AUTOSAR XML (schema 4-1-3)
standard types defined: boolean, sint16, uint16, uint8
package /DataTypes
  impl type Array_unit16_4: category=ARRAY, sw-calibration-access=READ-ONLY, type-emitter=RTE
    element Array_unit16_4: array-size=4, array-size-semantics=FIXED-SIZE, implementation-data-type=uint16
package /UAES/ASW/ApplicationDataTypes
  application array data type Array_T_q1_o63_DegC_s16_4: category=ARRAY, sw-calibration-access=READ-ONLY
    element Array_T_q1_o63_DegC_s16_4: category=VALUE, type=T_q1_o63_DegC_s16, array-size-semantics=FIXED-SIZE, max-number-of-elements=4
  application array data type Array_Tq_q0p001_kN_u16_4: category=ARRAY, sw-calibration-access=READ-ONLY
    element Array_Tq_q0p001_kN_u16_4: category=VALUE, type=Tq_q0p001_kN_u16, array-size-semantics=FIXED-SIZE, max-number-of-elements=4
  app type Curr_q0p136_A_s16: category=VALUE, sw-calibration-access=READ-ONLY, compu {phys=raw*0.136 for raw -INF..INF; unit A}, range phys -100..100
  app type T_q1_o63_DegC_s16: category=VALUE, sw-calibration-access=READ-ONLY, compu {phys=raw-63 for raw -INF..INF; unit ℃}, range phys -63..650
  app type Tq_q0p001_kN_u16: category=VALUE, sw-calibration-access=READ-ONLY, compu {phys=raw*0.001 for raw -INF..INF; unit kN}, range phys 0..50
package /UAES/ASW/CompuMethods
  compu method CM_boolean: 0=FALSE, 1=TRUE
package /UAES/ASW/DataConstrs
  range DC_boolean: raw 0..1
  range DC_sint16: raw -32768..32767
  range DC_uint16: raw 0..65535
  range DC_uint8: raw 0..255
package /UAES/ASW/DataTypeMappingSets
  data type mapping set DTMS_EPB_SysSrvAdpVDA
    data-type-maps:
      application-data-type=Array_T_q1_o63_DegC_s16_4, implementation-data-type=Array_sint16_4
      application-data-type=Array_Tq_q0p001_kN_u16_4, implementation-data-type=Array_unit16_4
      application-data-type=Curr_q0p136_A_s16, implementation-data-type=sint16
      application-data-type=T_q1_o63_DegC_s16, implementation-data-type=sint16
      application-data-type=Tq_q0p001_kN_u16, implementation-data-type=uint16
package /UAES/ASW/ImplementationDataTypes
  5 x impl type, all with category=ARRAY:
    Array_sint16_4: sw-calibration-access=READ-ONLY, type-emitter=RTE
      element Array_sint16_4: array-size=4, array-size-semantics=FIXED-SIZE, implementation-data-type=sint16
    Array_uint8_240
      element Array_uint8_240: array-size=240, array-size-semantics=FIXED-SIZE, implementation-data-type=uint8
    Array_uint8_256
      element Array_uint8_256: array-size=256, array-size-semantics=FIXED-SIZE, implementation-data-type=uint8
    Array_uint8_40
      element Array_uint8_40: array-size=40, array-size-semantics=FIXED-SIZE, implementation-data-type=uint8
    Array_uint8_8
      element Array_uint8_8: array-size=8, array-size-semantics=FIXED-SIZE, implementation-data-type=uint8
package /UAES/ASW/PortInterfaces
  29 x sender receiver interface:
    EPB_PbcInDataStorageRead: invalidation-policy{data-element=EPB_PbcInDataStorageRead/Val, handle-invalid=DONT-INVALIDATE}
      data Val: sw-calibration-access=READ-ONLY, type=Array_uint8_256
    EPB_PbcOutDataStorageWrite: invalidation-policy{data-element=EPB_PbcOutDataStorageWrite/Val, handle-invalid=DONT-INVALIDATE}
      data Val: sw-calibration-access=READ-ONLY, type=Array_uint8_256
    EPB_stPbcInDataStorageValid1: invalidation-policy{data-element=EPB_stPbcInDataStorageValid1/Val, handle-invalid=DONT-INVALIDATE}
      data Val: sw-calibration-access=READ-ONLY, type=uint8
    EPB_stPbcInDataStorageValid2: invalidation-policy{data-element=EPB_stPbcInDataStorageValid2/Val, handle-invalid=DONT-INVALIDATE}
      data Val: sw-calibration-access=READ-ONLY, type=uint8
    EPB_stPbcInDataStorageValid3: invalidation-policy{data-element=EPB_stPbcInDataStorageValid3/Val, handle-invalid=DONT-INVALIDATE}
      data Val: sw-calibration-access=READ-ONLY, type=uint8
    EPB_stPbcInDiagOperationMod: invalidation-policy{data-element=EPB_stPbcInDiagOperationMod/Val, handle-invalid=DONT-INVALIDATE}
      data Val: sw-calibration-access=READ-ONLY, type=uint8
    EPB_stPbcInDiagRequest: invalidation-policy{data-element=EPB_stPbcInDiagRequest/Val, handle-invalid=DONT-INVALIDATE}
      data Val: sw-calibration-access=READ-ONLY, type=uint16
    EPB_stPbcInFaultRecoveryRequest: invalidation-policy{data-element=EPB_stPbcInFaultRecoveryRequest/Val, handle-invalid=DONT-INVALIDATE}
      data Val: sw-calibration-access=READ-ONLY, type=Array_uint8_40
    EPB_stPbcInUnexpectedPowerdown: invalidation-policy{data-element=EPB_stPbcInUnexpectedPowerdown/Val, handle-invalid=DONT-INVALIDATE}
      data Val: sw-calibration-access=READ-ONLY, type=uint8
    EPB_stPbcOutDataStorageRequest: invalidation-policy{data-element=EPB_stPbcOutDataStorageRequest/Val, handle-invalid=DONT-INVALIDATE}
      data Val: sw-calibration-access=READ-ONLY, type=uint8
    EPB_stPbcOutDiagRequestAcknowledge: invalidation-policy{data-element=EPB_stPbcOutDiagRequestAcknowledge/Val, handle-invalid=DONT-INVALIDATE}
      data Val: sw-calibration-access=READ-ONLY, type=uint16
    EPB_stPbcOutDiagRequestStatus: invalidation-policy{data-element=EPB_stPbcOutDiagRequestStatus/Val, handle-invalid=DONT-INVALIDATE}
      data Val: sw-calibration-access=READ-ONLY, type=uint8
    gDiag_bDSMClear: invalidation-policy{data-element=gDiag_bDSMClear/Val, handle-invalid=DONT-INVALIDATE}
      data Val: sw-calibration-access=READ-ONLY, type=boolean
    gDiag_u16PbcinDiagRequest: invalidation-policy{data-element=gDiag_u16PbcinDiagRequest/Val, handle-invalid=DONT-INVALIDATE}
      data Val: sw-calibration-access=READ-ONLY, type=uint16
    gDiag_u8PbcinDiagOperationMode: invalidation-policy{data-element=gDiag_u8PbcinDiagOperationMode/Val, handle-invalid=DONT-INVALIDATE}
      data Val: sw-calibration-access=READ-ONLY, type=uint8
    gEPB_u16PbcoutDiagRequestAcknowledge: invalidation-policy{data-element=gEPB_u16PbcoutDiagRequestAcknowledge/Val, handle-invalid=DONT-INVALIDATE}
      data Val: sw-calibration-access=READ-ONLY, type=uint16
    gEPB_u8Pbcout_DiagRequestStatus: invalidation-policy{data-element=gEPB_u8Pbcout_DiagRequestStatus/Val, handle-invalid=DONT-INVALIDATE}
      data Val: sw-calibration-access=READ-ONLY, type=uint8
    gEPB_u8PbcoutDataStorageArea1WrtCnt: invalidation-policy{data-element=gEPB_u8PbcoutDataStorageArea1WrtCnt/Val, handle-invalid=DONT-INVALIDATE}
      data Val: sw-calibration-access=READ-ONLY, type=uint8
    gEPB_u8PbcoutDataStorageArea2WrtCnt: invalidation-policy{data-element=gEPB_u8PbcoutDataStorageArea2WrtCnt/Val, handle-invalid=DONT-INVALIDATE}
      data Val: sw-calibration-access=READ-ONLY, type=uint8
    gEPB_u8PbcoutDataStorageArea3WrtCnt: invalidation-policy{data-element=gEPB_u8PbcoutDataStorageArea3WrtCnt/Val, handle-invalid=DONT-INVALIDATE}
      data Val: sw-calibration-access=READ-ONLY, type=uint8
    gEPB_u8PbcoutDataStorageWriteArea1_a: invalidation-policy{data-element=gEPB_u8PbcoutDataStorageWriteArea1_a/Val, handle-invalid=DONT-INVALIDATE}
      data Val: sw-calibration-access=READ-ONLY, type=Array_uint8_8
    gEPB_u8PbcoutDataStorageWriteArea2_a: invalidation-policy{data-element=gEPB_u8PbcoutDataStorageWriteArea2_a/Val, handle-invalid=DONT-INVALIDATE}
      data Val: sw-calibration-access=READ-ONLY, type=Array_uint8_8
    gEPB_u8PbcoutDataStorageWriteArea3_a: invalidation-policy{data-element=gEPB_u8PbcoutDataStorageWriteArea3_a/Val, handle-invalid=DONT-INVALIDATE}
      data Val: sw-calibration-access=READ-ONLY, type=Array_uint8_240
    gNVM_bPbcinDataStorageValid1: invalidation-policy{data-element=gNVM_bPbcinDataStorageValid1/Val, handle-invalid=DONT-INVALIDATE}
      data Val: sw-calibration-access=READ-ONLY, type=boolean
    gNVM_bPbcinDataStorageValid2: invalidation-policy{data-element=gNVM_bPbcinDataStorageValid2/Val, handle-invalid=DONT-INVALIDATE}
      data Val: sw-calibration-access=READ-ONLY, type=boolean
    gNVM_bPbcinDataStorageValid3: invalidation-policy{data-element=gNVM_bPbcinDataStorageValid3/Val, handle-invalid=DONT-INVALIDATE}
      data Val: sw-calibration-access=READ-ONLY, type=boolean
    gNVM_u8PbcinDataStorageReadArea1_a: invalidation-policy{data-element=gNVM_u8PbcinDataStorageReadArea1_a/Val, handle-invalid=DONT-INVALIDATE}
      data Val: sw-calibration-access=READ-ONLY, type=Array_uint8_8
    gNVM_u8PbcinDataStorageReadArea2_a: invalidation-policy{data-element=gNVM_u8PbcinDataStorageReadArea2_a/Val, handle-invalid=DONT-INVALIDATE}
      data Val: sw-calibration-access=READ-ONLY, type=Array_uint8_8
    gNVM_u8PbcinDataStorageReadArea3_a: invalidation-policy{data-element=gNVM_u8PbcinDataStorageReadArea3_a/Val, handle-invalid=DONT-INVALIDATE}
      data Val: sw-calibration-access=READ-ONLY, type=Array_uint8_240
package /UAES/ASW/SwComponentTypes
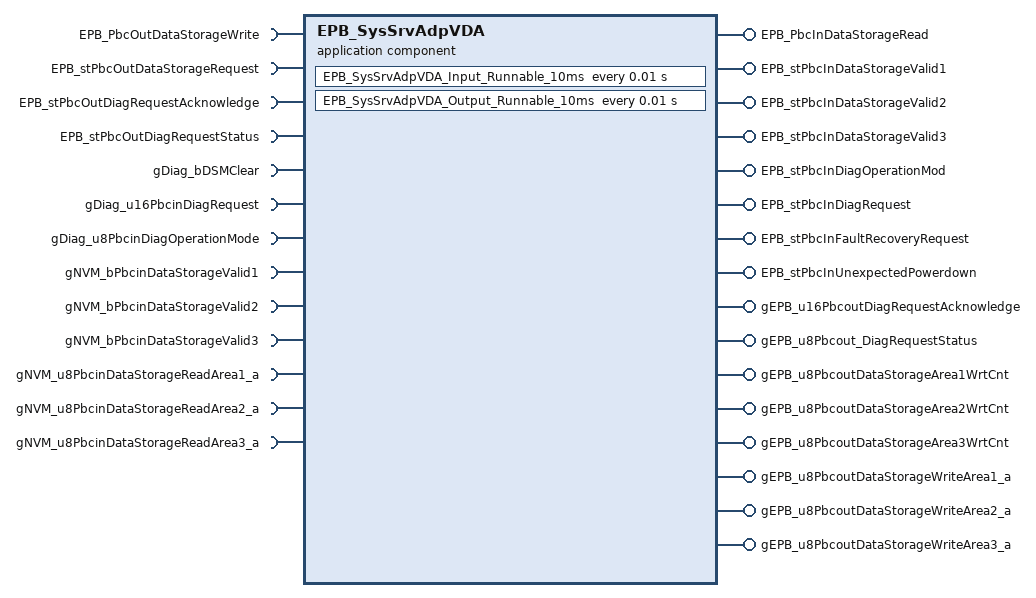
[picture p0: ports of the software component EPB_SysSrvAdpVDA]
  application sw component type EPB_SysSrvAdpVDA
    16 x provide port:
      EPB_PbcInDataStorageRead: nonqueued-sender-com-spec{data-element=EPB_PbcInDataStorageRead/Val, init-value=ComSpecf3d0d672_569a02da3f590a9c:[Cell003a5ef72e3_347f2b9380af2847:0, Cell1e5b45f543e_e158783d4a01d71e:0, Cell2ac8afe79aa_90a8b258906aa376:0, Cell31079542819_f583da6c34b4a5a6:0, Cell4e1492d10a7_e50fa48c31f36330:0, Cell529da6dda77_59de6bc3000fb334:0, Cell6668b0b0bc0_3b80b756d3fa7ef7:0, Cell78b5c64a6e2_ebde69c135075005:0, Cell8bfae43ef6e_6bffb3ed3a108b20:0, Cell96e5179533c_c107be038ff4ffde:0, Cell10f7f182345_4d95c3aac0845699:0, Cell111a955adcd_bed96221eb9df251:0, Cell12dcf29b5a4_dceddf5b2c2d8708:0, Cell131b73ec010_63733c77bab2f1b0:0, Cell14c1c1dbfa9_0d76ec14aedd536b:0, Cell1540ecd5bce_5a28f278ec4f5446:0, Cell1650de3cde7_69ad7e849fa770b8:0, Cell176eab8a163_da9c186df8bb7add:0, Cell1841ce47b55_cd2855371f7db6dc:0, Cell1906579acc9_79c0edbfacf9aca4:0, Cell2068281177d_b9a56413b9efef81:0, Cell2131e52c365_66338d14ba700c74:0, Cell220bdd21e13_80364d156b464962:0, Cell23333c2e77b_bb66b9ee56f4dc31:0, Cell248fba29fa2_2ad3a0dcbc4c91c3:0, Cell25d6aebec89_3ae1f0c4ddb84711:0, Cell260fcdf7560_8f9acdb3de58a439:0, Cell2771a41e34d_d16aa547594f8f99:0, Cell2825c2f0112_a612bc47642c047e:0, Cell29c2e5fc5ef_fd170d36a1ae2e72:0, Cell30ac36e6307_75ff511e67c23885:0, Cell31aa5fca867_d795da326959ced3:0, Cell32b82128fc6_836d81a8daee4c50:0, Cell33d368b73bf_14db24e7ad78e2d5:0, Cell34340d93035_9e71356eb53949b5:0, Cell35a4a7e09d5_7f2b6e92405df30c:0, Cell36130e82c2b_9b2263777aa89b7a:0, Cell37354d20141_467e5f96e3cf1abd:0, Cell38ea2c4d436_24f01e270efe751d:0, Cell39269afdf07_f988cbae13c05b09:0, Cell4082f4e1084_971c489743f7e5d2:0, Cell41cf4d3bc8c_2069c200a2ef2691:0, Cell42c0066c54a_b7b36f2d9e66b7dd:0, Cell43fc16137b6_536e789866dcb68b:0, Cell44c925db1d8_5f523d5d1b56247b:0, Cell459ead98a85_3a35bb2a07994f54:0, Cell46a2a47c67b_149ed0637357a623:0, Cell474a51bd061_9b4df34cfd52a47d:0, Cell48e9bbc6430_6dcecffa11ab92f7:0, Cell493e8f59e02_1a81b87641ff4f1e:0, Cell504852d3844_832bb538769a0795:0, Cell515e96dd530_aaaaf734293b71eb:0, Cell5221bf55d7b_e2ee0f0b61bfd7ec:0, Cell53f029d6407_31624cd165733836:0, Cell543e277509e_6b3ca17c3a913b5b:0, Cell5570095a137_c6fa70566aaa0b91:0, Cell56461e5e54d_9a8810294750e35d:0, Cell57583dea315_d53ca0f0eaad0947:0, Cell58eed438f34_5eeb50142033984b:0, Cell5998c1b072f_b401943fbb7e166f:0, Cell600650da9ff_7eaabd7c81027731:0, Cell61c5bcb3dc4_9c09b9fc1e132d81:0, Cell623104aa739_10a3054872c23e5a:0, Cell6305894c107_be7520ef35c23b1b:0, Cell6460a01b9be_aa9836c2fd2f179d:0, Cell6593e0146ed_bdaf8471969e671f:0, Cell6673f6947a6_728d4ac75759bae0:0, Cell6737346932d_2874e58596dc5e00:0, Cell68686eb5774_ad773492463c1312:0, Cell69ac94a0eea_b609a50790521bb4:0, Cell704c755afdf_145897225bbbaaed:0, Cell717403898f1_f3398d9e7d0d4f8e:0, Cell72dbbdb5ff4_7dd8ffbb08d20cdf:0, Cell733eb5b04e9_0827a58b1f21f964:0, Cell74b2c8e9b1e_6949e17e5a724958:0, Cell7597eed97ba_b544a9fbb566b444:0, Cell76d6c9e6715_27aae6776fca7644:0, Cell7734747be25_088fc9e8257ff7f6:0, Cell78ae4d22153_41cde50dfefaff55:0, Cell7947c5450fd_efc665b1098956b2:0, Cell8035f6cfc0f_7798a37e674d958d:0, Cell81ca7cec84d_1f72f6e3b240f772:0, Cell82e61a67cfc_27a83dbb1443ba04:0, Cell8395bfd65f5_b643c8e628ae2e82:0, Cell84bbe7580e8_c905ba3fc5e0b061:0, Cell851efcb6834_158fb6ceccc68378:0, Cell865e874af1d_b4e311918a2ee7b4:0, Cell876001d8e8f_fafa6ee92eac8a81:0, Cell88693598d56_0857caa5d13382df:0, Cell89b19f3a91f_d824e75b73498e18:0, Cell903560f873e_43ee811d96252c39:0, Cell91c2851a262_63f7b2847135e64c:0, Cell920fe60de3a_97b7eeb8d8c3543b:0, Cell933f91756f2_9985f533afc8b023:0, Cell945ecd083b6_bac21ae618fa16d1:0, Cell95500996561_cd4c1f72837cbd9c:0, Cell96fd76798b7_3e5bab9a71b3d1c1:0, Cell97bbda0cbe7_c6d753f1de058a30:0, Cell982cefa6602_1220ff59d5b75b96:0, Cell998fe8bc731_1d2d74d600dfb85b:0, Cell100a96f51a2_43a09efbbeea461d:0, Cell101d5584e56_002f6607e9196a69:0, Cell102ff4f267e_ad39ab1b123c8c79:0, Cell10384869123_19dc10029ad4c1e6:0, Cell1042eff1694_ab9b618a09feea11:0, Cell105e5f19ab7_0647992307dbd3a5:0, Cell106b8f84637_f2e50004aa8efa67:0, Cell107f1d64770_9776face47db1b5d:0, Cell108ea5f1fe3_4269b49575fed3a4:0, Cell1092f2c8ba1_82b7d9914fe39b0c:0, Cell1108b12f84c_45c9b0790232cad5:0, Cell11196b522c5_9c7e5f6b704a0ede:0, Cell112cae93cc0_75d4f8ef91a7aa5a:0, Cell11365f14de1_0930e8742c87bf4d:0, Cell114e937ccc1_5936b6a3f13d6add:0, Cell11585186506_f026c18c2ddf6eff:0, Cell116f0fcae29_93816c88b8a9d3e2:0, Cell1179af732de_c72d9bc3fa644a6d:0, Cell118688b3707_7a90743f3b55a8e6:0, Cell11920d2392c_330245abc45eecbb:0, Cell1205b0eb05b_e8012a34bd79db19:0, Cell121cad1db57_339e544408d232a3:0, Cell122fbfef642_e9962bf4da3f613c:0, Cell1233acba1f3_a32c0a332bbc91c2:0, Cell124022b1c8a_aa638c6d579c0630:0, Cell125fd8e5218_616f94d66df9db0a:0, Cell126278c08c6_d076d2f39b723680:0, Cell1277ee0144b_a334d28d22410396:0, Cell128ea80b0f9_469f304bf5a739a8:0, Cell12918f4e7d5_154d3e78560a9627:0, Cell1309a51e074_311b83e575f7f89b:0, Cell131630b9d33_74f36ae7dc8def45:0, Cell132f50d7a5c_0a46cd70aeb69ab0:0, Cell133efe1ec80_35c32b7a5cab5a90:0, Cell134b6e05afd_c5d6a0c2d24337e5:0, Cell1352ff813d9_87295eec4aa08373:0, Cell13647229225_2bd52deb58cd67c0:0, Cell13739bd5955_bd2446bf5e71782d:0, Cell138c8e051e6_693238c1ecea0226:0, Cell1396ec31ebb_8eb059af97c10207:0, Cell140d19edde1_e7a67b6eaac29b2e:0, Cell141a711e33f_3a7e27dd2d0da86c:0, Cell14248cb0d59_23189124af474c53:0, Cell1438db9da4b_102d72e01bf76e6f:0, Cell144d59ee0bd_0a29edc2218b4002:0, Cell145e5e3bf61_4e43b96f19cc4ff7:0, Cell1466fc2b207_851f694ec732f395:0, Cell1472a9e550d_4479560440410480:0, Cell148b734eb02_b26a49c78e1abf5f:0, Cell149d04fc07c_e16ff6c0e3b7b655:0, Cell150d06436af_d32ea7417aeae1a1:0, Cell15197773278_72532d8b9e0eb650:0, Cell1529f53b508_6ca43ca43debcd9b:0, Cell153b9673f2c_632ca512c31a1467:0, Cell15493584750_e68232ec1b3527e1:0, Cell15513f5f92c_a9eb2be567245b60:0, Cell156ed367704_3ef80158bb4ba7e6:0, Cell157a64bacc7_6fa56e7242858c0c:0, Cell158a05d7f0f_e66daf5bc72ff937:0, Cell1591cee0224_a08f1047c99faf0b:0, Cell160ad01ae3a_cfc15dedb82d29b2:0, Cell161d0ef7c46_ea9016c8192352e8:0, Cell162c955819d_a959060c25c915fc:0, Cell1634dd6d5b1_67c4fa306dfaad2e:0, Cell164d14585cf_0d791536d1d7c400:0, Cell165f1a48748_a0d3d34597ff14d7:0, Cell1660dd681b3_d8cac3d16fca2b4f:0, Cell167532a936a_c1083cee060ab379:0, Cell16894f4a328_c54c4624057a8bec:0, Cell1690aeec632_2fe7dd40e6a74a43:0, Cell170b530c50f_0e24e0759d6e2576:0, Cell171a3ceb881_bf8c03a765acd22b:0, Cell1729018f442_a408277af54eaf92:0, Cell173529df27f_f3641661a83c3e05:0, Cell174e70a23b9_70b78deba8a08faa:0, Cell1750e400bc6_86558a9c355167c5:0, Cell17600828a63_7435871818fd663a:0, Cell17752581c7d_7ae6ad9f0f6cc450:0, Cell178c095cf7c_5bee7cc7c23b2338:0, Cell1798dc723ea_77dafb791e7e9699:0, Cell18088b84fad_1476799e62722a7d:0, Cell181429a7084_6e03297a25335f4e:0, Cell18270414281_715feed164c4e1e5:0, Cell183de271431_59722a1e6dfb13ae:0, Cell1848f83dd98_681f670d68220959:0, Cell1857f6f7497_efdad1cd488219a5:0, Cell1868b47f6bd_b8dfa159e34d6022:0, Cell187c8823cfd_d66f67ecacfad817:0, Cell188aaa77f60_dc75f5bdc46eb55e:0, Cell189668b49be_bb44100728b86c04:0, Cell190d7381c84_7002fde9fd1cbf78:0, Cell1914121ffba_5cc11b33bbba86fe:0, Cell192bbc13a18_2c40bd4174dcff02:0, Cell1939b92eaf0_318df7ee5cec326a:0, Cell194e00d17d4_897f23aef7bc4cc0:0, Cell19556930156_4cbf6f55188445ee:0, Cell196a154f056_198e0655552c03f4:0, Cell197a3840cb3_5ade1fd39b3f676f:0, Cell1988ace7449_e612f7730888fa2e:0, Cell199a3681df9_83efba1715266f3b:0, Cell200087cb143_fa71375c8d9e2aec:0, Cell201b03aba5c_44b1cecf42fce5fa:0, Cell202c8d6c096_d6d3c7043453e5e0:0, Cell20333d00a65_a3f618297c31a8ef:0, Cell2041f7c7d72_f4a27a069df79e6d:0, Cell2059abf2983_5f0a41eb8b7eabf3:0, Cell20695f73ff8_bdb29e9f611940c5:0, Cell207791443dd_a6df34dad4e18287:0, Cell208b4739c5c_4f5b61a50d7f1fe7:0, Cell209fd27a922_bf8dfa66cf707a7a:0, Cell21064878f76_8269a8608b8a5c8b:0, Cell211594fbf19_0d8c1d5a4e3ed5cb:0, Cell212733bb204_f670abe5cd194769:0, Cell2139f5a9da8_908e2655481496d3:0, Cell21407476ecd_405ac3220ce509d9:0, Cell2158e137af6_31e134980d15e918:0, Cell216b58fb861_bc95c818f0d365a3:0, Cell2177b58cb25_f838f30a8cb0b4ec:0, Cell21890f542d5_e7ad4116bf1d478f:0, Cell21984b06fe9_703f95d0cdd6fbb1:0, Cell2202365ab92_7b71206c3efc9961:0, Cell221e63c28c9_243fe93250b30459:0, Cell222c34b1af6_be5c20c400d717bd:0, Cell2238803af53_a3933384a2c9aa53:0, Cell2242faf3813_a58bd6f442f4cf59:0, Cell2253d2bfc64_564136c7d659703c:0, Cell22618137519_f03c63a786328728:0, Cell2275f341d80_04dd02205c6213eb:0, Cell2285f6fcc93_3e29a5952ab529a4:0, Cell2291e42d910_802ad79a8414e14b:0, Cell230044e96f5_eb6e2e9bef1bae08:0, Cell231b24547bc_ba396589f1e0185c:0, Cell232f5e2ba8e_47f6ae54cab9bdf6:0, Cell233a50eaae8_88b1b29b5345ab10:0, Cell234d8812d45_858b1ac27a6a5a27:0, Cell23526d39b32_ab2f48a2ed727889:0, Cell236bb397ff8_2a4724a8ffa58872:0, Cell237acec9acb_7c935eec8c7d36a0:0, Cell238f28fc003_93d4149b07c91974:0, Cell239c0737224_ad2167e409ea11e4:0, Cell240b553cfbb_575eed68bb9b25e6:0, Cell241de979ee4_f5497fa5f58a4a10:0, Cell2423c7d099a_9d64cad50f745740:0, Cell243b77d9c3f_d6f9f583c334b5bf:0, Cell244931ceb96_a2fa9f3fcc6f52a2:0, Cell245d07e142d_ef4e27258786fcf3:0, Cell246187a61c5_4d68325be6b16dec:0, Cell247bbd81238_db0a9946334c94d3:0, Cell248d450b637_5e8cce639876250b:0, Cell249591ed961_a72ac6eca8d3e33f:0, Cell2509fa04c39_edf71e494d1c0fac:0, Cell251e1af419c_1791ce57e18e2c21:0, Cell252cf772a8c_217acb606889fc17:0, Cell253162fcf51_45ecca1a524159c0:0, Cell25464f5c1ec_6f529cdc77d917fa:0, Cell255b16575d0_3fde3add8fa3a808:0]}, provided-interface=EPB_PbcInDataStorageRead
      EPB_stPbcInDataStorageValid1: nonqueued-sender-com-spec{data-element=EPB_stPbcInDataStorageValid1/Val, init-value=ComSpec4a0e0181_c4c047acc1af9626:0}, provided-interface=EPB_stPbcInDataStorageValid1
      EPB_stPbcInDataStorageValid2: nonqueued-sender-com-spec{data-element=EPB_stPbcInDataStorageValid2/Val, init-value=ComSpec471af1b6_d61227f10a1b489c:0}, provided-interface=EPB_stPbcInDataStorageValid2
      EPB_stPbcInDataStorageValid3: nonqueued-sender-com-spec{data-element=EPB_stPbcInDataStorageValid3/Val, init-value=ComSpecf17d96da_7efbffbc34b506a3:0}, provided-interface=EPB_stPbcInDataStorageValid3
      EPB_stPbcInDiagOperationMod: nonqueued-sender-com-spec{data-element=EPB_stPbcInDiagOperationMod/Val, init-value=ComSpecbd3421d8_15113bca5c939145:0}, provided-interface=EPB_stPbcInDiagOperationMod
      EPB_stPbcInDiagRequest: nonqueued-sender-com-spec{data-element=EPB_stPbcInDiagRequest/Val, init-value=ComSpec96d26215_9a89be3dd2cc4669:0}, provided-interface=EPB_stPbcInDiagRequest
      EPB_stPbcInFaultRecoveryRequest: nonqueued-sender-com-spec{data-element=EPB_stPbcInFaultRecoveryRequest/Val, init-value=40 x 0}, provided-interface=EPB_stPbcInFaultRecoveryRequest
      EPB_stPbcInUnexpectedPowerdown: nonqueued-sender-com-spec{data-element=EPB_stPbcInUnexpectedPowerdown/Val, init-value=ComSpece6124d51_bcdf5fd65462ad06:0}, provided-interface=EPB_stPbcInUnexpectedPowerdown
      gEPB_u16PbcoutDiagRequestAcknowledge: nonqueued-sender-com-spec{data-element=gEPB_u16PbcoutDiagRequestAcknowledge/Val, init-value=ComSpecacb83174_51461f52c6998cab:0}, provided-interface=gEPB_u16PbcoutDiagRequestAcknowledge
      gEPB_u8Pbcout_DiagRequestStatus: nonqueued-sender-com-spec{data-element=gEPB_u8Pbcout_DiagRequestStatus/Val, init-value=ComSpec6cd16599_7bab502e6c32b829:0}, provided-interface=gEPB_u8Pbcout_DiagRequestStatus
      gEPB_u8PbcoutDataStorageArea1WrtCnt: nonqueued-sender-com-spec{data-element=gEPB_u8PbcoutDataStorageArea1WrtCnt/Val, init-value=ComSpecf9b1b6aa_3c4790537328e85b:0}, provided-interface=gEPB_u8PbcoutDataStorageArea1WrtCnt
      gEPB_u8PbcoutDataStorageArea2WrtCnt: nonqueued-sender-com-spec{data-element=gEPB_u8PbcoutDataStorageArea2WrtCnt/Val, init-value=ComSpecbe127572_2a140405108644a1:0}, provided-interface=gEPB_u8PbcoutDataStorageArea2WrtCnt
      gEPB_u8PbcoutDataStorageArea3WrtCnt: nonqueued-sender-com-spec{data-element=gEPB_u8PbcoutDataStorageArea3WrtCnt/Val, init-value=ComSpec7799b90b_f315d803155cede1:0}, provided-interface=gEPB_u8PbcoutDataStorageArea3WrtCnt
      gEPB_u8PbcoutDataStorageWriteArea1_a: nonqueued-sender-com-spec{data-element=gEPB_u8PbcoutDataStorageWriteArea1_a/Val, init-value=ComSpec726fea48_b2538984992dd78f:[Cell0cc3ce6d787_ba1a292e39c8f51f:0, Cell174c18c62a6_93430dab8d39ca79:0, Cell22d167e70df_5e11f1a2ede3ba11:0, Cell359a106a847_0b6c8a1ec832d081:0, Cell43a9678befc_02b773e1f9fe38b0:0, Cell58683f3f881_74711807962880bb:0, Cell66d05ae27fa_d354372509efa56d:0, Cell74f1e14f4b5_5844165d7b27d347:0]}, provided-interface=gEPB_u8PbcoutDataStorageWriteArea1_a
      gEPB_u8PbcoutDataStorageWriteArea2_a: nonqueued-sender-com-spec{data-element=gEPB_u8PbcoutDataStorageWriteArea2_a/Val, init-value=ComSpec8e5ef6a0_67658702874d9fd5:[Cell047ed5976b9_629eb377c425a8f8:0, Cell1b4411826b2_d94701e348492115:0, Cell2a51701059d_3c977e3fef7940b9:0, Cell34e65b1dcbb_6ca561eed0574b21:0, Cell4d7a0a1af83_8117c32077fe7298:0, Cell56ab2efcabd_eee81878e383705e:0, Cell634b2a8a389_bce317fa05b9f838:0, Cell7b1c48a6d25_594c67bd8e024879:0]}, provided-interface=gEPB_u8PbcoutDataStorageWriteArea2_a
      gEPB_u8PbcoutDataStorageWriteArea3_a: nonqueued-sender-com-spec{data-element=gEPB_u8PbcoutDataStorageWriteArea3_a/Val, init-value=ComSpec203a9b5c_5768b24c1c3a1265:[Cell0977d4b1fce_cd08fc8f7cfcd47b:0, Cell1d2b0145b58_70eb15bf130cc4ca:0, Cell2cfa8b8db3f_115b8e6e6f513a64:0, Cell3f346ac0a53_5ee3463e29dcfa71:0, Cell4a7cb94761e_db028856db7be2a1:0, Cell55877a7f487_801fb81c030256f8:0, Cell6ee524a6685_270f301d1b9d3ff6:0, Cell782817852cc_fa9ce84da11878db:0, Cell8577470b3c8_472306a43d518d71:0, Cell9c8aa45e52b_c02ed8e33891a6e2:0, Cell106acdfdb03_043cbcfbc012b7bc:0, Cell1127d610535_57c0496bcddb458f:0, Cell12000a85f58_2033dce8929e279d:0, Cell1358d912b32_9f062aeb72e97475:0, Cell1484000bfdf_bf0ca2a3a8716907:0, Cell1569b19aede_c2ae8dbaef50647b:0, Cell161332e798f_fb4d430d0549120f:0, Cell17b1a8d8bb4_06d1f03dfd411a88:0, Cell18fc72b3adb_4b16427ff2bdbe13:0, Cell190fd987eaf_467244fb21cfff20:0, Cell20e0e963b5e_4e62c8843b2759e0:0, Cell2132003ee34_fe957238cf599831:0, Cell22877a79178_452d154ff19903c5:0, Cell23522b3fe8f_dd1e8c758c52b102:0, Cell2437f3b9c24_aa013004c1abec9c:0, Cell259932dfbcb_c98c08d9d1dd451c:0, Cell264b0a59458_f9abb020892d0206:0, Cell27648f57059_b29b506a9efca319:0, Cell28dc65f5710_b47ecf22837ec5de:0, Cell29fdc26d571_d04be92b237f912b:0, Cell30e71c9963e_ed79dcd947010a2c:0, Cell311cad6c7fe_94739cf29bf0572e:0, Cell32262b653c6_d8b3659b74b9ab5a:0, Cell33c914a9eb7_531e0f1e29488be1:0, Cell3456b5321f9_a4ab60a267d3f2d4:0, Cell35fd838fd25_1c4e74f67610a300:0, Cell361cf1bd2c5_1687dd927d1d8e14:0, Cell37d359ec3ba_84fa21a39072878a:0, Cell38ec29b59c6_22d6eaa990ec27f4:0, Cell390e38da33e_421ec5bf32060f80:0, Cell40a24c44086_f1b1788ae1a54530:0, Cell4123594e0d7_ce92e0f3c89a0d66:0, Cell42cd0d15943_09ff9d894d072f02:0, Cell43d092b668d_c31bf531e9ffa82a:0, Cell44b4df65858_99d0773532c0ce87:0, Cell454f1368bad_54dd589971fb13f1:0, Cell46449778539_a40b6c8fe0b0a1cd:0, Cell471b37b2fb8_8cc7487b22e31702:0, Cell48fff3631f0_9ccd7756bfbac4d8:0, Cell49db277c118_13b4d40b6a817027:0, Cell506dffd892d_0f41d43d92e337d5:0, Cell51bc39fa7c0_56323552b12c1a91:0, Cell525daf49bc6_92aa8b6917ca5a25:0, Cell5357bedd111_671b1c527e958db1:0, Cell54ca38e3891_add42bb63bd31830:0, Cell55b3d096834_a7a219fb64a93bb1:0, Cell562091d99a1_0adbff7e2ab6a8ba:0, Cell5727ddde5af_9f69bbcc3c1ef81a:0, Cell58dffc431f9_c7faf9834fe2281e:0, Cell59d27ef0d45_7b10d6f445eb02a1:0, Cell600f96df4e9_94c5e9a74821597c:0, Cell6183aa0ace4_aa97003f72d7d4fe:0, Cell6213d4b0b05_3a29d17c2b22f498:0, Cell6363c31e6a2_306c9c215fa107b4:0, Cell64ef0d44ea6_191ec62e774c5230:0, Cell65dde6437c3_69e14f76817c0266:0, Cell666ccae5aab_803f4507f98c3478:0, Cell67616ab7d81_a11ff807a6fab584:0, Cell6848228b947_0877f3b09fabd605:0, Cell69b00300f7a_06011cbbf3416763:0, Cell703714584e3_0a88b3613d51de0d:0, Cell715f55d68fb_8279c33c7cde6f62:0, Cell72752cc7a8f_10b99c32546e2d8c:0, Cell734da0486b5_ee3a4070aab28117:0, Cell7497597c1f2_52dcecff4d310208:0, Cell75ce2f60f98_93efecf55413dfd4:0, Cell76fd885579f_247ad53cf0a79313:0, Cell7766317c5bd_7ee77d4be4e245c6:0, Cell784d7963803_9c8e8f3fc0873ef7:0, Cell79b6baaf9a8_c5ae6180036fe4cc:0, Cell806640d86a4_e87623d3a48bb4da:0, Cell81bc9955f5b_26cbae125a5fc20a:0, Cell8206bee89fa_6ef6cd1cec3e0178:0, Cell832858a6563_19856ce8e8901f51:0, Cell8457cb116e9_f0bd01a1e9775296:0, Cell85d2a0db53b_ad8b31af535ac6d7:0, Cell86f0d8ca835_9c245af46323067b:0, Cell876d6f59efd_b6bb339aab49aed6:0, Cell88d48e17666_c7e81a3bfb846709:0, Cell8937b57c497_5efc5f1a45b572c4:0, Cell902f9ee0449_2415b044def51fcd:0, Cell9154a920a10_8e591f1cfa2e9f58:0, Cell92235f3331c_683c165e351ed652:0, Cell93566c8c7bb_acf4eed785663fcb:0, Cell942c8838baa_0d75002a903a0f7d:0, Cell950ca4d17fc_38117e9a2625fc59:0, Cell96cc96db542_98c21d3116e8c755:0, Cell97d04dea68b_dc81faace1b75469:0, Cell98da37b0587_5166dedc8be1cc6d:0, Cell99d7a2f0771_77fef4ca3ef786fd:0, Cell1008057cfd5_61921360ad230841:0, Cell1015a7ee399_621fd4a084fa1829:0, Cell1026e82e3a1_df55ba92ec8cc2d2:0, Cell10384d00f9b_0783024b163d1cc5:0, Cell1040aea4ef7_1a4eaf76f1991d3d:0, Cell1056fc40921_68074dc774ca2716:0, Cell10626f8ab53_5015f21a9d31afc5:0, Cell107bb24b2f6_e1ad6541c555c035:0, Cell1083cadd14e_2566159bf9eef598:0, Cell109a1ed45ee_768b891c5b1a4b39:0, Cell1104f4cab12_aacf6b2e61e84685:0, Cell1111f285bab_6d62c04335414254:0, Cell1120ef50a58_1c5121518585c10a:0, Cell11317e1d39d_c899c9551e38d69f:0, Cell114ebb0376a_cc859ebcccc0e827:0, Cell115fcdd6688_f68bf069394f5cb0:0, Cell11691c32f56_29bef999205b4287:0, Cell117324f762f_4ffcc65133c31556:0, Cell11894ced29a_735ca8ffd732e9bd:0, Cell119c1773abf_dc9df2b0e46a798e:0, Cell120a35149a7_ddf2f9a7647c1e48:0, Cell1218d803010_8b8bd3e547a8991b:0, Cell122046b97a6_17140e360cc43d82:0, Cell12396857604_85d116f25c5824b0:0, Cell1243eb82a65_2d38135ef5e10491:0, Cell12527353dab_0b90351e6db9a26d:0, Cell126408871ef_addeec2e1164519a:0, Cell127e28cd9fb_e87b5b9c4aec7a27:0, Cell12814bac650_d82cecc6f3652a60:0, Cell129614709a8_6679994e79c01b6f:0, Cell1309a126c33_0b5b6dae5adef5c2:0, Cell13175153a83_06afdc75e52e59b6:0, Cell1323071c925_c3bbafe3b4cb024d:0, Cell13397d3d374_7157e948820765bb:0, Cell1347caa5e90_1fe1332a7f36d2fd:0, Cell135012a310d_723ffdf003ee5ad3:0, Cell1360bbe66b6_def1eb62df517e3e:0, Cell137a7815ec7_54a491d1257453af:0, Cell1388712b543_45a4cd241a135eac:0, Cell13925555b81_59a81e35dc9870b1:0, Cell140bbf25538_a34b6e00ed394305:0, Cell141f836f88e_794cfd56d5e12473:0, Cell142e044406a_4f2f1f1847becccc:0, Cell143dc2466b0_c9e0c8dfad591e03:0, Cell14435c8d6af_18772129ba5a1987:0, Cell1451006fdb5_97554b4264a66cc0:0, Cell146193b14ae_d0c825be7b3b455d:0, Cell14751cc7271_a5293af53b72bd60:0, Cell1489ecf50e4_f765a61575183967:0, Cell1499255899f_63aa9a54323206e8:0, Cell150c1a8f48f_16822c7d7e094f64:0, Cell151368a0478_3ca49585e4267f24:0, Cell15247c65e96_c08c23bb8c0758d3:0, Cell153bf347dc2_d235defd15d2008d:0, Cell154567ff304_ad6cd4fd5cf25a7e:0, Cell155b3276a45_465d58f182f551b9:0, Cell1565ef7e604_cb64a905dd1dc38e:0, Cell157d811c50c_7e0329b554250672:0, Cell158cbaa874d_5e8e108bb87f27a2:0, Cell1590bf2be9d_4c8095ee0a9b9e4e:0, Cell160028433e7_9e99ba5fd8929ea0:0, Cell161d0b99e9e_bde1ffb1af6095cc:0, Cell1627164eb24_675d70d53985c840:0, Cell163798416a7_b80d38db98ad6f1a:0, Cell164ee67d0e4_36d6319f4a67c9a2:0, Cell1652b64e78e_0ed92192224c5c95:0, Cell166aea795cf_6992b44d44ee2eb5:0, Cell16756c20a9d_0883b0e82d08c0b8:0, Cell16814f17d3a_aab767be671e5b24:0, Cell169e28d4f1e_7f4338969472804a:0, Cell1700dd6981e_cf08af07954d1cb0:0, Cell171d1913fcd_4b0422ed2ca2bc57:0, Cell172375e6077_fe3da6b14a79493f:0, Cell1732a89e08e_67bfd6b1ec889b06:0, Cell174dfbd88b9_39079172db2311a0:0, Cell17508587556_bba39d00029ce960:0, Cell17685277c89_cee25cf990bb5960:0, Cell177c9b49c8e_38503495f888a699:0, Cell178862e8acb_0be9647dffb90ea3:0, Cell179bb401d8b_460d390a2cf3611e:0, Cell180bca7bb5a_4232fff1ff3d93d8:0, Cell181d90bbbbb_cf33edc1797cec50:0, Cell1824044cb8c_badce7f8b9ae68a8:0, Cell1833b171592_7a8074f63a4a849c:0, Cell18446b93235_e47024b20f1e777a:0, Cell1854c850c0c_234b2534008697ad:0, Cell1864ec5d8e0_fce230d5a8546a74:0, Cell18722f3742a_7842c97bfdb8bd69:0, Cell1885d4d6203_05f1d35d4326f8cb:0, Cell1893a9cd849_a8acd16ce96d4258:0, Cell190209ed36f_77ec02d6797b9e5b:0, Cell191002ed11b_30661a153ae53228:0, Cell192d0ebc078_6851314c6320d04f:0, Cell193df86d1ec_b2fd255639b99468:0, Cell1940b95de9d_ed0786bb3ee091de:0, Cell1951c848d5d_bb5a461957283997:0, Cell196851ae76b_d47f62af04e1281b:0, Cell197f385a03c_f63b0d1274e00dba:0, Cell1989f4bc164_06709e7688760c7d:0, Cell199e9d0ce13_a7f09c47d2df522f:0, Cell2005c60f72d_e942587a1b4bdd35:0, Cell20188a5f907_3bee3b144f6ad86e:0, Cell2022ce8ee02_fd77e8ebc44b203a:0, Cell203854b4f8b_b00e2d333e2cc1b6:0, Cell2048a440689_97dd266074986f1a:0, Cell2055aad9eb2_2e943a3f1449bd6b:0, Cell20651ffad6a_48d8f70eeeacc0fa:0, Cell207c15ac792_bda765e9b0f7f81a:0, Cell208a6d366bd_6ab664e99c19b2e0:0, Cell209f0504a44_d4f5f0092e64a5f2:0, Cell2105ef6eddb_fdd81a659ba6db85:0, Cell21165b4f88a_c114d4abf55c91ee:0, Cell21269a1656b_2471d591ea9283e8:0, Cell2135ef8a49b_0109a4cf4d21bf75:0, Cell21409813ac7_89492403625f867c:0, Cell2157e6ac364_675a15bf02a75966:0, Cell21626f1050c_a20d66e843c3f914:0, Cell2177e75b908_dae4f7aafb64c7dd:0, Cell218212f948d_da1153460270a79d:0, Cell219cf99618e_b2204f86c93a7bad:0, Cell22002b7c4a8_91d330c8b3e53cc6:0, Cell2210f0989f6_1f5571e0521d5768:0, Cell222f8246aa6_f53bd72ba07107a2:0, Cell22369f4bb9b_e8813c4020651c26:0, Cell22491aab1a9_ce17c14a00a965f5:0, Cell225514097d1_3190f702065e6ba2:0, Cell226d5f7490a_343a9430278c7304:0, Cell227297c0d73_e7937f2bbc648727:0, Cell22806ea0387_40877906dc33eeef:0, Cell229c85d677a_8e1435fc895dbcfb:0, Cell230a912b04c_c49e28d657a67375:0, Cell2313e749ea7_755371f0c409b7f6:0, Cell232d9ecaace_c7ae0f934e0b3b08:0, Cell233e04051b4_510faa6470e3c2b3:0, Cell2343f7682a0_a416778e78650a2b:0, Cell23522634807_b949b567ba30d881:0, Cell23635559e5c_086bd36ad70df3df:0, Cell237be904870_c98197a5ec3bc4f8:0, Cell238026533d0_5b2c2721782629eb:0, Cell2392a637d22_e60feebf21a02b15:0]}, provided-interface=gEPB_u8PbcoutDataStorageWriteArea3_a
    13 x require port:
      EPB_PbcOutDataStorageWrite: nonqueued-receiver-com-spec{data-element=EPB_PbcOutDataStorageWrite/Val, filter=data-filter-type=ALWAYS, init-value=ComSpec1ccb9a5f_f3ea63a4ee9864d9:[Cell097ad10db7a_8f0ad701e6dec749:0, Cell1a8d5036c4c_52d1374c0bc18f84:0, Cell2a898d50f1c_857ece91dbb47a6c:0, Cell39ef74f1660_f2273ea0f9513417:0, Cell4ba405dc71b_94bbc0157610a60a:0, Cell51d78ce5930_5303b1541fb48fef:0, Cell6e40a556bd2_c0e9b9abdbcfc14a:0, Cell79fbd96152e_be947a54f998e5a1:0, Cell803c6176794_64089b05747f97c6:0, Cell9329d1a1889_347e4ddd0f59977d:0, Cell1018d1450a3_531139e2c769f9d1:0, Cell118387f6978_19d6526fca02fa12:0, Cell12f86deeb10_7182f90c45335ee0:0, Cell138a51889b6_b91bb87836fa35d2:0, Cell14be9a25afe_abb84f61f050616c:0, Cell15b812eaf3e_0da1e4c662dee93c:0, Cell16d810209f5_27a3c160f5103439:0, Cell17d26b55062_66a16937d6f92412:0, Cell1844914e7bb_784883d38083162e:0, Cell19e1cdf69db_e55bab115cfdf7ad:0, Cell204394b092f_1a290c3881769cc4:0, Cell21a0c173d7a_7c1da7fbba4075fc:0, Cell22db92d299b_1467572efc7e5283:0, Cell235343d73e8_2d9c06538cc7210e:0, Cell24fccf70205_020b9432e0034b35:0, Cell250f91d799b_08bb537b37b595e1:0, Cell26db72898c8_1d3bba05dd180429:0, Cell272e9e58234_79133fd88431c39d:0, Cell28077079681_9f75f970bd9a6f8e:0, Cell29db1271ebf_fa50e2a282644c24:0, Cell30c6cedca38_7c81ab117bdeae9f:0, Cell31f15cdb2d5_ae124aeec0203a9f:0, Cell32130527e2f_b879f4e1775bb368:0, Cell334351ee2a7_21e9cc4be1769202:0, Cell34809968876_c701d761f3fb1911:0, Cell35b326d8d59_996bccf2c3c8444f:0, Cell36584bf2d99_1389338e0ab263bd:0, Cell37cc6e3f5d5_e845cb33c800ff58:0, Cell38691746608_05241939bb072da8:0, Cell397f82473cb_732edae24fe83df1:0, Cell40eb534b09f_91b5de57e616c3ac:0, Cell41d9ac3e3fe_ad988ee0baca1800:0, Cell4299b00a882_24b3659696b9a326:0, Cell4316da98a32_7ed75baf8a888fba:0, Cell44b21d5bccc_0131b99816d7656a:0, Cell453ec238c32_42713016c2345613:0, Cell468e03cbe16_21ccc53cf6e693dc:0, Cell47ac6d495c0_4c4876bf2296980f:0, Cell48ae3e3088d_d09f44164d314f92:0, Cell49c272ec048_0069e3ed4f72dae1:0, Cell50686721b71_f0990519f7d32474:0, Cell51114d92e1e_c3e96301d4797822:0, Cell524a220d042_1f8b77003312383e:0, Cell53e77592be7_091c8474f4eb9462:0, Cell549a0150fa1_03bd1c083d754e3d:0, Cell553c2893103_6f70f7e339349be0:0, Cell5631ea92048_5f382da394cf6fa0:0, Cell579d1988fde_90dd1fcb7e20b0af:0, Cell58f1f7bafa9_9a2a9b1e14b2148a:0, Cell5993368640e_6fd38f858c50c7c8:0, Cell60399c5f2ab_9897d19b73d61d3a:0, Cell61a02547420_059a6e02f3e0645a:0, Cell622bdb0c607_f634f8544e5d99b6:0, Cell631099f69f7_2c3604f1c7308b96:0, Cell64830491b18_1dcbd0ba7b5578e0:0, Cell65aef7532bc_0d98d053097d861b:0, Cell66c354ebcde_212e0b5c4aa7ed94:0, Cell67bae915761_281d941b3c168d52:0, Cell682cde7b2e0_baa2092bed17c9ed:0, Cell6926eb2fb23_0421f192741d1c92:0, Cell705c7026b16_7c8ed76897e49842:0, Cell7170174e5fd_9e66f3ac56125fd3:0, Cell72be9a834e1_d88a9b6d19a07438:0, Cell734457c8639_3244af53aac0ad89:0, Cell746dd9447d9_f86dbafbb2c02fd5:0, Cell75893bbc100_69429df42d3fc578:0, Cell7660eb16453_767b510b9331b413:0, Cell779ea380c01_128ac04c98b45faa:0, Cell78d1fe17364_d43c2a3156ac43a7:0, Cell79d826be43d_2feb36b907907c66:0, Cell8093d0a1099_35af3331a4747cc9:0, Cell8129eec7e78_23b173db022bf6d5:0, Cell82e7a03c4c8_193c247a1428c956:0, Cell83122791b6d_dcd68737c92d61af:0, Cell84ceb8c279a_16c53da082f5da98:0, Cell854e49d6f8d_27bcef7d314173b0:0, Cell8697d7c8841_272a2b1d73cf3ccf:0, Cell879f7fbcc2d_1f107eb098173d16:0, Cell8847fa0262f_1319e4caaba075da:0, Cell8907b71ca19_ac8e415c9aa1efe2:0, Cell90ad459952e_020241fdab1c3f3d:0, Cell910c2afa629_43e581db568a2cda:0, Cell929fa82e57f_f482e82b5da71711:0, Cell93fd9f6444e_4eb5f5d3d64fbbce:0, Cell94f31b02694_dfccc8698c340d08:0, Cell95623f9cc5a_c267f25a39264fa4:0, Cell96277705b31_67446bb03779843c:0, Cell9768854d39e_2e0c956a783e078d:0, Cell9877fc50dda_2b05b1ecc5b25b1d:0, Cell99f7d322c0f_b2c7e72f91713c43:0, Cell100bb43474a_95a2cbafb581455a:0, Cell1018a72a282_2f17c822170b6ffb:0, Cell102cf0dd5c7_d8a7b377f67bebc1:0, Cell10328738cee_f0e7f5db3a34095a:0, Cell1040e54fdcf_8e88a8289d1b266e:0, Cell105a9a39ce9_09ff9a09da2ad80f:0, Cell106d674af70_a4b6a1218907e794:0, Cell1074d8a8fe0_fe2fcfbc6c931640:0, Cell10884097558_6c56ddf19264e285:0, Cell10970f66709_ffc5e1fe686ecb41:0, Cell1105a14f6f7_eab6487a8e4c6e0e:0, Cell1119b6b48be_2e33ed64af23bf8b:0, Cell112ea1f34a2_e4d22a4063d00585:0, Cell113353d134b_5c71474d7fff7192:0, Cell114fb64acda_dc71a5d0f159b42e:0, Cell11548b3e09d_15a86b25da436ee8:0, Cell116ca61897a_d0b154ea2755b748:0, Cell1176816fd67_f98073f0ebc88e8b:0, Cell118c902d44e_89e089d6aec63f9e:0, Cell1193dd0ddea_8d526722f95dd223:0, Cell1206d933e1c_887ca6f487c1f5aa:0, Cell121dfaac5ce_1e3131e1c2c13d75:0, Cell1220d33715a_d523ae2f9597e42a:0, Cell12388b27203_f8e4f3ca65171b61:0, Cell1244635e706_64f7758bed2ab33e:0, Cell125f6af7976_99d67acc6afe70c3:0, Cell1264a51fe18_62043602069afc7e:0, Cell127be32d34e_90adeb76845ebc3b:0, Cell128a7ce0fcc_2d48ae8acbf700d1:0, Cell12989468ffc_1856ba91ec127611:0, Cell1305ef96281_a89c3ca6efcd3699:0, Cell131b3e8648d_4f1ccd196dfe1993:0, Cell132dafc45da_a3cb749c72424cb9:0, Cell1330e01c48a_7096483be236f999:0, Cell1343093085e_67969be26498b17d:0, Cell135bb7d9f8b_f4c8f2430a9e71db:0, Cell1365fdd19a0_3281845f34060dbe:0, Cell1373da24f88_9f4e7af6c5de4173:0, Cell13823914373_edf2d6f118e00b85:0, Cell139490b8aa3_717c86fb74478626:0, Cell1404f43e4ef_504541671b3aba5a:0, Cell141a59c185c_8839eb97066f054f:0, Cell1425ead4b4b_f5679a718cec9372:0, Cell143690134b9_c53a38a030df309f:0, Cell144487b5f73_5280cffc98c99923:0, Cell145e4ba0d05_a675981147e41410:0, Cell1466e13af85_d70e3ec9ff752923:0, Cell14762732cea_6167eb16a26f09db:0, Cell1481b34d860_f9111384407e808e:0, Cell149338247cc_3d78c390075f04ef:0, Cell150aabb020c_2f9445cffee886c5:0, Cell151fb8b362e_09c84db6bf51d653:0, Cell1525f8d37e4_4370afb5e96eb473:0, Cell1532c09b763_f8bad420d2c44d99:0, Cell154a835018e_be913592ace9a3c3:0, Cell1557337eb30_4168320bbf7f3c20:0, Cell15658784c72_6dc0e9ac3375d676:0, Cell157aa3dfdc7_6659fc11b6d58ec8:0, Cell1585455c74b_5098bc1f6f5ef236:0, Cell159d3eed698_9a302539d881e128:0, Cell160d20a39d5_a42e709ac3c014cb:0, Cell161f3dedcf5_ea543f214e286efb:0, Cell1621faa8cec_af715150b284128c:0, Cell16362a2ccfc_bc7bdd89c51fc3db:0, Cell164af17fb63_d5929b23b97a82f3:0, Cell165cc495cba_67bc2923bd07e538:0, Cell166315e578f_75fe76098c801325:0, Cell167f0a3fe00_1ef111b02e2fb65d:0, Cell1689b5c7ae1_e7a4213b6a2f0a9a:0, Cell169ae945ac0_7789bd88177dd9d6:0, Cell170aa9731bd_3670f160c178adeb:0, Cell17158d9897d_d7dcd6e565014ada:0, Cell172a86f7e8a_cf8e73884e6413ac:0, Cell173f221ee7a_0687e969524a758b:0, Cell1747362d5ec_adee5fc73791c966:0, Cell17542538f75_7188b9587a7af3b4:0, Cell17677c68ecd_6bc94ad74ea08422:0, Cell17761f6a6f2_97c13d85a54713be:0, Cell178fe9e7d9e_5e5311b4b42d207c:0, Cell179a40838e7_cdc50b03f2bccbdd:0, Cell1809e2a5c55_1a26d543ddd7f9f3:0, Cell181f816b236_a0ce111b4b270192:0, Cell18225c70bd7_f81c88b828cb8038:0, Cell183f6d5ffec_64875fdf9d40abe8:0, Cell1845fdc874c_10c23d45dfb2476e:0, Cell1854fd39132_caab98a0e5fef39b:0, Cell186adbf8a77_0b8bdf9395c841da:0, Cell187ea9646bf_98fdef03df846d37:0, Cell188f038e547_4bc47daecab52bf5:0, Cell18931e47886_c767da0bb4a17a6b:0, Cell190fd645789_19b6554832c16090:0, Cell191896ecb58_9eba6a5be73b1720:0, Cell192b465c75b_930b58f353e821b4:0, Cell193eecb92c8_4b78591b5b410b5d:0, Cell1940453afc6_6549c28b8cb75658:0, Cell19531cd6a76_bcf3dd8814219591:0, Cell196e6e1e187_8241b34c7fa91418:0, Cell197f1940679_2b50f76c6da2531a:0, Cell198b978fe69_d01eb05005316470:0, Cell199c453bafd_ed6e374df71e709f:0, Cell200c3d14a89_6471da4ab1cf24cf:0, Cell2011f4bb70a_91e0edd308c58f18:0, Cell2024a4f9db6_26795c4bad42fe06:0, Cell203784f1e0b_478061f118367f11:0, Cell204ddd407b2_a7ea7dc13974e4a4:0, Cell205ee3a8fdb_1336e31325e864e6:0, Cell206880d73c9_fb99b96092c5c645:0, Cell20756979a88_e70b2e4464d92a6f:0, Cell208123254f0_a5804e2cc5264ec5:0, Cell209bb0b2a95_7f2e62225c46f8f4:0, Cell210744966d0_c31b96589fa5b0d8:0, Cell2110f85c55d_d5f3ee8270b330aa:0, Cell212a2728e5b_214b629654f83798:0, Cell213fa4059e3_a396c52860a598a0:0, Cell214ea8c988a_e5b52d6884f42892:0, Cell2155c818f4c_23caa54a63264af5:0, Cell216d190dbfc_63fc79552d5b7be1:0, Cell217aefabde9_d5c08f81b72f1aa7:0, Cell2183e82ba10_26ebe502c3752706:0, Cell219bcd24583_6f33b8d55453c40e:0, Cell220bb4608ad_5664c4d218f03e4b:0, Cell2219a0a0f37_420ecd4250dc24cd:0, Cell2223d223a51_727084ef5e706f4d:0, Cell223e8baf388_121db6b282852d93:0, Cell224decbb2a5_4ba959f6f9712cbc:0, Cell2256bd35040_62b27beaedc5a146:0, Cell226667aecd4_0dfaeb7d60c4aeea:0, Cell22772a6439b_1dedb245c317f6d5:0, Cell228a787279a_a17824d20aa29193:0, Cell2290f4eb6c0_ad9ae83cd91df014:0, Cell230c97c4f75_353e342c14221e3e:0, Cell231d1fd204b_c35a2a803ace224c:0, Cell232dcd7c03b_890d96c3e5031e32:0, Cell2335d6e8a6a_1018476d6d836888:0, Cell234860c9bed_10ebd1fe8af0398c:0, Cell2359aac1bb6_e0392848d96e79c3:0, Cell23653097e5b_ea2a0c6a151b320a:0, Cell2371aa4945e_5d90c94dc294c9ed:0, Cell2384f32167e_905f4ce3561df73a:0, Cell239247fd650_73d267a62488d15a:0, Cell240ce12bb6f_be34ae5bb6f63fb5:0, Cell241dfccb300_360b7b6b4404d666:0, Cell242768ddf7b_48952c8f64f141f7:0, Cell24354ba35de_cece9562b15b1ec0:0, Cell2440d78f4a8_6c1c2c757f00243f:0, Cell2456740b40e_7494474652d43d79:0, Cell2468f020ac5_3dc5ab607c6a0add:0, Cell247c6ca58e6_6f3085be06a8474b:0, Cell2482b90c85c_534485ee8bf8d51d:0, Cell249a5b4880a_20371807fe630be0:0, Cell25077ae941f_8269239a5c203dd4:0, Cell251cd5ae0d3_f28f232330d1ddae:0, Cell2526d21a3fd_6f0c801387e98746:0, Cell2536a34e941_d4f31d377035383e:0, Cell254366a45bf_e11606fc97a206f8:0, Cell2550e6edb84_291fd51785ef23ca:0]}, required-interface=EPB_PbcOutDataStorageWrite
      EPB_stPbcOutDataStorageRequest: nonqueued-receiver-com-spec{data-element=EPB_stPbcOutDataStorageRequest/Val, filter=data-filter-type=ALWAYS, init-value=ComSpecf8883d70_ab1dcf91da40acce:0}, required-interface=EPB_stPbcOutDataStorageRequest
      EPB_stPbcOutDiagRequestAcknowledge: nonqueued-receiver-com-spec{data-element=EPB_stPbcOutDiagRequestAcknowledge/Val, filter=data-filter-type=ALWAYS, init-value=ComSpec14548705_f8a765f05ffa751b:0}, required-interface=EPB_stPbcOutDiagRequestAcknowledge
      EPB_stPbcOutDiagRequestStatus: nonqueued-receiver-com-spec{data-element=EPB_stPbcOutDiagRequestStatus/Val, filter=data-filter-type=ALWAYS, init-value=ComSpeceb451772_b4b983db390cf332:0}, required-interface=EPB_stPbcOutDiagRequestStatus
      gDiag_bDSMClear: nonqueued-receiver-com-spec{data-element=gDiag_bDSMClear/Val, filter=data-filter-type=ALWAYS, init-value=ComSpec4651e553_44fa98d174c29234:0}, required-interface=gDiag_bDSMClear
      gDiag_u16PbcinDiagRequest: nonqueued-receiver-com-spec{data-element=gDiag_u16PbcinDiagRequest/Val, filter=data-filter-type=ALWAYS, init-value=ComSpec6b9b3b22_4b8ef965e0e07ceb:0}, required-interface=gDiag_u16PbcinDiagRequest
      gDiag_u8PbcinDiagOperationMode: nonqueued-receiver-com-spec{data-element=gDiag_u8PbcinDiagOperationMode/Val, filter=data-filter-type=ALWAYS, init-value=ComSpec93dd7b49_33d0aad8775d9192:0}, required-interface=gDiag_u8PbcinDiagOperationMode
      gNVM_bPbcinDataStorageValid1: nonqueued-receiver-com-spec{data-element=gNVM_bPbcinDataStorageValid1/Val, filter=data-filter-type=ALWAYS, init-value=ComSpece4028a2d_2a406b00fbbf9741:0}, required-interface=gNVM_bPbcinDataStorageValid1
      gNVM_bPbcinDataStorageValid2: nonqueued-receiver-com-spec{data-element=gNVM_bPbcinDataStorageValid2/Val, filter=data-filter-type=ALWAYS, init-value=ComSpec9322b75c_f1fb11835a8dfec2:0}, required-interface=gNVM_bPbcinDataStorageValid2
      gNVM_bPbcinDataStorageValid3: nonqueued-receiver-com-spec{data-element=gNVM_bPbcinDataStorageValid3/Val, filter=data-filter-type=ALWAYS, init-value=ComSpec515b2cd0_d89736da4d9c1513:0}, required-interface=gNVM_bPbcinDataStorageValid3
      gNVM_u8PbcinDataStorageReadArea1_a: nonqueued-receiver-com-spec{data-element=gNVM_u8PbcinDataStorageReadArea1_a/Val, filter=data-filter-type=ALWAYS, init-value=ComSpecfa247fd9_d4ae585d4c8b4676:[Cell0b99fecaff5_6fda5fbe34e7325b:0, Cell154416ff67c_6db8f92b0bef88c7:0, Cell2940a30b384_d39659d27586b8b7:0, Cell3a81789c151_9b6d11eabe400bce:0, Cell4730b3565a7_73bfa7e0fad2e472:0, Cell55473c5d2ce_df26cf78ab4ad002:0, Cell644c729f68b_619ede8979919d28:0, Cell732936ce906_7244d0a64546dfeb:0]}, required-interface=gNVM_u8PbcinDataStorageReadArea1_a
      gNVM_u8PbcinDataStorageReadArea2_a: nonqueued-receiver-com-spec{data-element=gNVM_u8PbcinDataStorageReadArea2_a/Val, filter=data-filter-type=ALWAYS, init-value=ComSpecd1ef580b_547a68f7052fedb1:[Cell08209bdf935_7282a6f7d60400c6:0, Cell18642fb0819_a036ce7208dbc0df:0, Cell277f9259f22_3008c28a034ef657:0, Cell321b978fc1e_df184bf6d0499ef5:0, Cell4aa2b0feb9a_c852c84cfb6b984c:0, Cell5d6b0380edc_2ef729662787519b:0, Cell684e60a3c82_86d0ff8a17d06658:0, Cell754d28ca12e_1343a9fe41dec127:0]}, required-interface=gNVM_u8PbcinDataStorageReadArea2_a
      gNVM_u8PbcinDataStorageReadArea3_a: nonqueued-receiver-com-spec{data-element=gNVM_u8PbcinDataStorageReadArea3_a/Val, filter=data-filter-type=ALWAYS, init-value=ComSpec2c4cf2f6_b512417a73262f4a:[Cell0c08ea3a7d9_1265d16680d8a711:0, Cell1e73b73e5ce_66bb653945af76e6:0, Cell273a0a73c8c_274e4fb9c983d2c2:0, Cell33fee7cb697_18a8282edff9c797:0, Cell430b6f96c6b_092554907d1c6469:0, Cell5e642c59977_a63cf773cc6b2d81:0, Cell6d0d449fe9a_e578d7b5eafdf72c:0, Cell72ccf6b3604_532c585ec5b7cf9c:0, Cell875a8799189_88af2cb59f94d039:0, Cell98b4e82df46_444474e8eb3bf7ac:0, Cell107722cdda4_0461d02cb19458a1:0, Cell11606e504c3_a285533d53ad110f:0, Cell12995f7351f_c05d00ed074f4d58:0, Cell13d871f25f1_390b55039902ec3a:0, Cell146f8bf31e1_1c9a395014784c80:0, Cell1550090bd4d_e670dcd9e4a9dcef:0, Cell1653c76ad1c_1a1ca0880ac2f997:0, Cell17fc17dd0db_ecf711687573cc19:0, Cell18ee2ee3405_e80cbf997707a28d:0, Cell19183b4ddb1_28ab21606f76c464:0, Cell20bffbb252f_eebd8a9b3a9d4178:0, Cell21628a2a47c_e247c2b65054ee93:0, Cell2273adf3293_b93a6ee8f446562c:0, Cell23a87d006c2_3bb33b35ce3e52f5:0, Cell245b6be1582_13d53a2a8d89cea3:0, Cell251a1c40c00_c9537e0afa33a426:0, Cell268639289a9_df56ba55664b744e:0, Cell27438b54da3_485d95f2284cdd2b:0, Cell28d855f2513_94ae61558f6b4bb5:0, Cell29dcedd2ce0_b9c157425a9dfea2:0, Cell307f17b4d29_343a73ce8d32afca:0, Cell31110cd4ad3_027e93fbff792740:0, Cell3249762d642_1fb2bca2e589836b:0, Cell33f804d2b21_fffa3649fa4719e7:0, Cell34de3745f1c_ba73587a5a9b1903:0, Cell3560fc772c2_f1abbc6c43817d0e:0, Cell36358780864_5b47992aef818282:0, Cell3719dcdeac3_3a35252382356675:0, Cell38886485689_3fe50b4fd1fc8234:0, Cell39f4bb45f72_2581cae6da531cea:0, Cell4057144f375_108a90bba119517d:0, Cell417c8ab260b_2392b9cd543d39f3:0, Cell428f0e0069f_cdbbcf08198f5101:0, Cell436953e0af2_08c613144b15d477:0, Cell4451c860224_4c0d334abbf7970f:0, Cell45fc8c123e2_cbda59d44a8a7107:0, Cell46d3d1c3afd_bf2e0f3f04f59b7f:0, Cell4706f21a876_f73b8369cfda685d:0, Cell48c6fe91e7f_e946745808d0d446:0, Cell494e8e31b84_c5307173c88ccd8d:0, Cell50e87855439_a580cce8faae9b34:0, Cell516e115bcd9_343b21e06935176f:0, Cell528655f1b29_b7d1de2dd247d75b:0, Cell53290d5a91e_52f70f64c497fc70:0, Cell5488cd4bf2e_556f6907bb2ed4b7:0, Cell55eab389c8b_674465290464f535:0, Cell56436e60447_faa2bfdbae1a0d2d:0, Cell5757d9f1680_4b34b72316cf27a9:0, Cell582bfc90dc4_1e2692ad8013f3ea:0, Cell59667702ac2_c51e11fad45f3651:0, Cell603d1c0e2a8_17ea2be937e854e8:0, Cell611fe899666_f2e322c2a5f19b44:0, Cell62a11bebe00_a883c92a47726685:0, Cell63bc627746b_bc7a2884c4503d41:0, Cell6494c7f464e_ef1c0bf82f052016:0, Cell658e1a8d810_f57815a50b0b025a:0, Cell66b65d71170_09bc5f90a037ce3d:0, Cell67d60d80069_c7f7e0b0f8a4a7ce:0, Cell680ec7fdba9_aa1862ef5a7b0740:0, Cell69dd0bc996e_fe78c8a8877eefbb:0, Cell704c2d3ba6c_77aceb0834097aee:0, Cell71752dbcb7a_12876bc3d9d077f4:0, Cell72fd40d248c_2cff789b97ecc775:0, Cell738b5626d2f_381beb87a2d203b5:0, Cell740c400f37a_5ee6fb2d6cebf1a0:0, Cell75beef07283_617762ae49b9019b:0, Cell7624688e0cd_f4557ef31e7ae888:0, Cell7707ae7f1ae_987cf77ae7ff7b30:0, Cell785cb7fefa6_60dc72f528d4a2ec:0, Cell7947a641222_c4514a28b3bb9cd6:0, Cell8023c71e184_eb4582050ed061a7:0, Cell8170ebfe340_97ded20a65f65738:0, Cell822f33ed936_9d3c7c81ebca5daa:0, Cell83a0b0f8e5f_5a8452b22cd05fbd:0, Cell84dcdb2cc2c_6e08f26ebb0b80fb:0, Cell8519a8009bd_bb7d2e83b4b719ee:0, Cell86b20a9602b_5179b52593d8e107:0, Cell87f2ff0d01c_ee3b3e49a64f93e2:0, Cell881faf8b1b4_931e5f1c6d3d9b7c:0, Cell89105018174_76f49680a284a371:0, Cell905eaaf5a5b_d6bbb2d16fd8d835:0, Cell91eadbd3ff7_87433a363b06cc41:0, Cell922676f9fc8_fa38233b5fbf19dd:0, Cell9387d6c618f_a2aba3520a35bc66:0, Cell94a4c07cf59_0af7b2778f33f18d:0, Cell9535225acbc_61b3db7dcabe2805:0, Cell9612c4f6259_74cfd3de849435cb:0, Cell97f45d86b70_b749dd2f781af1db:0, Cell980595978a6_605b9c44d4456eae:0, Cell99748b24b7b_87084da1545bdb8c:0, Cell100fd8dcea2_ed6f72ce851cede8:0, Cell101ac673f90_884103bba2e32d4d:0, Cell102cd9e3e1e_8fe6303e0e763793:0, Cell103bef3e069_e3d30bd9e7291c9f:0, Cell10412b84f6e_89481c7812baf841:0, Cell105fcd5e127_cf0b266100fcc11b:0, Cell1068450676b_dcb1ce9860473892:0, Cell1070a7e4c0f_148d6d46e755355d:0, Cell1087e20f485_41b81fea50034da2:0, Cell10993de40be_b1ac420f24f91ee1:0, Cell1101f0b78e0_4cd6e132b1dad847:0, Cell11170ece6ca_a44ec852e812590a:0, Cell11292086153_b54d0ce6a81075e9:0, Cell113e8cda5fc_c8170d858377a7b3:0, Cell114010560e7_9ad197e1c27d8e43:0, Cell1155815a3ce_2fd585376a8a2ba4:0, Cell116fa612dde_37fea5d50c3c722b:0, Cell1175b26eefd_4c2bb43ea9ef9e49:0, Cell11868001bff_9f355dafc503cf15:0, Cell119ce26e0e8_61d851b53a96c5b3:0, Cell12000269819_cda8f48cc986461c:0, Cell12133ac8d1f_8e08218e4d6e3c5c:0, Cell122c1465646_a812c00daeec8865:0, Cell123fd2c41e4_16aea4ac9e12b6ae:0, Cell1244d56d72a_2076c26b85eabc35:0, Cell125844ea168_d53bd94f5284076c:0, Cell12683b60dda_df6ba3088a962e60:0, Cell127084a5785_71f6f42cb7a52272:0, Cell128b6c1c020_b942c5957ddf4a42:0, Cell1298c99ef11_cb7f42ac585bd73c:0, Cell130d9628c1f_03a4f685e3d3f052:0, Cell131e1e0dd4f_4ec2a25fa7ec9970:0, Cell132be8de100_415573ee5759425c:0, Cell133c96f3e25_2f05ca1b8992e139:0, Cell134fbba894b_4aeb71fe9b274ed0:0, Cell1350064274d_16a35cc170505806:0, Cell136f1b792eb_2b5c3b0b87fe7da7:0, Cell1376c743c1e_cb49598a88c07263:0, Cell13830e1574a_15f73946c7bdfd84:0, Cell139d9071ecc_2252a4644949d829:0, Cell140e8252b48_194d307dfb463be0:0, Cell141dc2d7f35_336b683330d550e6:0, Cell14263ed5d4f_9f512831e5564d0e:0, Cell1431ecac14a_eae034c989cea93c:0, Cell14417a3f4de_7d785a27f97ce658:0, Cell1457ee10fca_b7cd619809412945:0, Cell1464eb9fdc1_0ef6174c633743a6:0, Cell147081401e3_ad521997e582c12d:0, Cell1484e7451ec_78e616dee8c63dcf:0, Cell1492af0cfb9_44a02553d199e6a9:0, Cell1507e995adc_b3f5ae97a21e589f:0, Cell1510272acf4_b8a4da11c3651b5a:0, Cell152652ea744_45a688bbc133a666:0, Cell15328481d75_c25bd3c616a42070:0, Cell154243a69fc_a6a0a6bcb20396a0:0, Cell15588188a38_c468bc128ea2faf8:0, Cell156cc7b9fbd_3257d83219943b94:0, Cell157deb55fe9_1411c1828feea8be:0, Cell158b0709204_dcfe8c814e401e52:0, Cell15947fe781b_444ed6caf2d8c39b:0, Cell1606add312e_e94a75e929195dca:0, Cell1616d30fb7e_77debbb98952b1fa:0, Cell162a7898d1d_e7b4e1d392872ad1:0, Cell163c7267416_09d825b37c2b6598:0, Cell1641733075c_106ff648120b2939:0, Cell165b7bbd4e5_50917647a36a0dac:0, Cell16657876663_28a541330715f71e:0, Cell167a0f9d0cd_f8ef397882913280:0, Cell1687e770223_c6b8176b1d0e164a:0, Cell169d917b6fe_7f70a33c0c07603b:0, Cell17078f15d1e_2375dea573ec7576:0, Cell171b4491875_41b6e6e42069f322:0, Cell172a49fb2ed_4638db3ff535419a:0, Cell1739fea82ff_074a5bd77f162d0a:0, Cell174b1f33d4e_ed3d61c42c436942:0, Cell175c00e47e7_d22820f3763899ce:0, Cell176ea7b212f_488583a5f6407f0a:0, Cell17700eaf1a0_f23d23001e4aa6b9:0, Cell178804809dc_ebf242c380a2cded:0, Cell17996cd086e_1e567b83afab4cf4:0, Cell180fb8a243c_e73be5ce2c6e80f1:0, Cell18154a3f998_1f0b4f110adc9bc1:0, Cell182d3ef982e_a8a3875571e86940:0, Cell1832525c6a7_a43397e9ae5ec32a:0, Cell184a37e563a_9db80377994c0f85:0, Cell185c8c5f954_9df31e18f7452ed8:0, Cell186225e08c4_94b0a6acc9aa5d85:0, Cell187e2dbd5df_7c17a58fd419c9d8:0, Cell188b73241a5_c9653886c47f721c:0, Cell1893c007269_851a2f44975ef5e9:0, Cell1907908fd20_f8b952d1f2956825:0, Cell191409c717b_812623a32e9e43b6:0, Cell192c60a316a_a5d84c5b313190e8:0, Cell193d3e800b7_f8a8bb9b14b69b34:0, Cell194d6733b70_4d8398e8831d600f:0, Cell195ae6b52ba_52437c6a77059d39:0, Cell19638d0c2be_a162fc3f8a2c4bec:0, Cell197f119c68b_a924847a60ea6988:0, Cell198ea3000f2_7b1887a264524d29:0, Cell199d7a66c10_91b0b04b088871d0:0, Cell2009bcf8129_3d78db47c5342ba8:0, Cell201cba089a1_45700816a5d95ff8:0, Cell2022895e561_235a2e9dc850644c:0, Cell203302d461c_53c8ba0fcb4fa695:0, Cell2047802fb6a_d7ffd247c61d5f9d:0, Cell205df94ee82_9bc5de3491b11371:0, Cell2067c631734_3cebda7337963942:0, Cell2071fc1e2b9_1794352cbda1f9f7:0, Cell208b34266f8_fe84607655b3fd02:0, Cell209eed03cd2_26eb93f4633c4ba3:0, Cell21069cb0253_66a8801d5775e142:0, Cell2119a85179f_6bab825a516b1299:0, Cell2120fb5d927_7f119d73723dfbee:0, Cell213f3a64b53_b2449158c974399d:0, Cell214f548fe30_89ab1303c834cbb6:0, Cell215d4912450_215fe916c71ae83f:0, Cell2162e81ec42_d1dd5407e72f5502:0, Cell217ad06904a_d0f5fc50dc5037f9:0, Cell218f4a5062b_55b0f76b0bcebe1a:0, Cell21920200c21_8a5cff5969e235a8:0, Cell22093071d28_ca787914106fea16:0, Cell221f5e3629a_52a6abf79e5f16cf:0, Cell222d69ceace_585c7b60bba5ce2c:0, Cell223abeca4b2_ffa22d17ce6aaf41:0, Cell224cb5f4db6_6149002db4dd2f75:0, Cell22511c6e9bd_d7c27f99a28948e4:0, Cell226156f09c7_76f2e88443e2a2d0:0, Cell227575c62e8_0e646fc8dcf7d43d:0, Cell228ea3156f5_307f13ba2493602b:0, Cell229c1808301_b79e6bc963cafdd5:0, Cell2301726f688_2fa78af4b4264d40:0, Cell23127f976c2_cbb85fd012a4d261:0, Cell2325ae6c6f6_31f4babe7834cf01:0, Cell23335b596d6_d7e433f5ecc1e3c8:0, Cell2346885a881_d6bd5d2cc236fc53:0, Cell23547ad72c2_b399de324cd5fb2e:0, Cell236c4e8d107_952ea561a03866cf:0, Cell2377b9fed19_e22a56be11eeef04:0, Cell2389d3a1941_2b6ac6517fd5701f:0, Cell2392457620b_df87850bbe0ddbc8:0]}, required-interface=gNVM_u8PbcinDataStorageReadArea3_a
    behavior EPB_SysSrvAdpVDA_InternalBehavior: data-type-mapping=DTMS_EPB_SysSrvAdpVDA
      init event EPB_SysSrvAdpVDA_InitEvent: start-on-event=EPB_SysSrvAdpVDA_Init
      timing event TMT_EPB_SysSrvAdpVDA_Input_Runnable_10ms: start-on-event=EPB_SysSrvAdpVDA_Input_Runnable_10ms, period=0.01
      init event EPB_SysSrvAdpVDA_InPut_InitEvent: start-on-event=EPB_SysSrvAdpVDA_Input_Runnable_Init
      timing event TMT_EPB_SysSrvAdpVDA_Output_Runnable_10ms: start-on-event=EPB_SysSrvAdpVDA_Output_Runnable_10ms, period=0.01
      init event EPB_SysSrvAdpVDA_OutPut_InitEvent: start-on-event=EPB_SysSrvAdpVDA_Output_Runnable_Init
      5 x runnable:
        EPB_SysSrvAdpVDA_Init
        EPB_SysSrvAdpVDA_Input_Runnable_10ms
          data-read-access:
            9 x access:
              IN_gDiag_bDSMClear_Val: accessed-variable=gDiag_bDSMClear.Val
              IN_gDiag_u16PbcinDiagRequest_Val: accessed-variable=gDiag_u16PbcinDiagRequest.Val
              IN_gDiag_u8PbcinDiagOperationMode_Val: accessed-variable=gDiag_u8PbcinDiagOperationMode.Val
              IN_gNVM_bPbcinDataStorageValid{1..3}_Val: accessed-variable=gNVM_bPbcinDataStorageValid{1..3}.Val
              IN_gNVM_u8PbcinDataStorageReadArea{1..3}_a_Val: accessed-variable=gNVM_u8PbcinDataStorageReadArea{1..3}_a.Val
          data-write-access:
            8 x access:
              OUT_EPB_PbcInDataStorageRead_Val: accessed-variable=EPB_PbcInDataStorageRead.Val
              OUT_EPB_stPbcInDataStorageValid{1..3}_Val: accessed-variable=EPB_stPbcInDataStorageValid{1..3}.Val
              OUT_EPB_stPbcInDiagOperationMod_Val: accessed-variable=EPB_stPbcInDiagOperationMod.Val
              OUT_EPB_stPbcInDiagRequest_Val: accessed-variable=EPB_stPbcInDiagRequest.Val
              OUT_EPB_stPbcInFaultRecoveryRequest_Val: accessed-variable=EPB_stPbcInFaultRecoveryRequest.Val
              OUT_EPB_stPbcInUnexpectedPowerdown_Val: accessed-variable=EPB_stPbcInUnexpectedPowerdown.Val
        EPB_SysSrvAdpVDA_Input_Runnable_Init
          data-read-access:
            6 x access:
              IN_gNVM_bPbcinDataStorageValid{1..3}_Val: accessed-variable=gNVM_bPbcinDataStorageValid{1..3}.Val
              IN_gNVM_u8PbcinDataStorageReadArea{1..3}_a_Val: accessed-variable=gNVM_u8PbcinDataStorageReadArea{1..3}_a.Val
          data-write-access:
            8 x access:
              OUT_EPB_PbcInDataStorageRead_Val: accessed-variable=EPB_PbcInDataStorageRead.Val
              OUT_EPB_stPbcInDataStorageValid{1..3}_Val: accessed-variable=EPB_stPbcInDataStorageValid{1..3}.Val
              OUT_EPB_stPbcInDiagOperationMod_Val: accessed-variable=EPB_stPbcInDiagOperationMod.Val
              OUT_EPB_stPbcInDiagRequest_Val: accessed-variable=EPB_stPbcInDiagRequest.Val
              OUT_EPB_stPbcInFaultRecoveryRequest_Val: accessed-variable=EPB_stPbcInFaultRecoveryRequest.Val
              OUT_EPB_stPbcInUnexpectedPowerdown_Val: accessed-variable=EPB_stPbcInUnexpectedPowerdown.Val
        EPB_SysSrvAdpVDA_Output_Runnable_10ms
          data-read-access:
            6 x access:
              IN_EPB_PbcOutDataStorageWrite_Val: accessed-variable=EPB_PbcOutDataStorageWrite.Val
              IN_EPB_stPbcOutDataStorageRequest_Val: accessed-variable=EPB_stPbcOutDataStorageRequest.Val
              IN_EPB_stPbcOutDiagRequestAcknowledge_Val: accessed-variable=EPB_stPbcOutDiagRequestAcknowledge.Val
              IN_EPB_stPbcOutDiagRequestStatus_Val: accessed-variable=EPB_stPbcOutDiagRequestStatus.Val
              IN_gNVM_u8PbcinDataStorageReadArea1_a_Val: accessed-variable=gNVM_u8PbcinDataStorageReadArea1_a.Val
              IN_gNVM_u8PbcinDataStorageReadArea2_a_Val: accessed-variable=gNVM_u8PbcinDataStorageReadArea2_a.Val
          data-write-access:
            8 x access:
              OUT_gEPB_u16PbcoutDiagRequestAcknowledge_Val: accessed-variable=gEPB_u16PbcoutDiagRequestAcknowledge.Val
              OUT_gEPB_u8Pbcout_DiagRequestStatus_Val: accessed-variable=gEPB_u8Pbcout_DiagRequestStatus.Val
              OUT_gEPB_u8PbcoutDataStorageArea{1..3}WrtCnt_Val: accessed-variable=gEPB_u8PbcoutDataStorageArea{1..3}WrtCnt.Val
              OUT_gEPB_u8PbcoutDataStorageWriteArea{1..3}_a_Val: accessed-variable=gEPB_u8PbcoutDataStorageWriteArea{1..3}_a.Val
        EPB_SysSrvAdpVDA_Output_Runnable_Init
          data-read-access:
            access IN_EPB_PbcOutDataStorageWrite_Val: accessed-variable=EPB_PbcOutDataStorageWrite.Val
          data-write-access:
            8 x access:
              OUT_gEPB_u16PbcoutDiagRequestAcknowledge_Val: accessed-variable=gEPB_u16PbcoutDiagRequestAcknowledge.Val
              OUT_gEPB_u8Pbcout_DiagRequestStatus_Val: accessed-variable=gEPB_u8Pbcout_DiagRequestStatus.Val
              OUT_gEPB_u8PbcoutDataStorageArea{1..3}WrtCnt_Val: accessed-variable=gEPB_u8PbcoutDataStorageArea{1..3}WrtCnt.Val
              OUT_gEPB_u8PbcoutDataStorageWriteArea{1..3}_a_Val: accessed-variable=gEPB_u8PbcoutDataStorageWriteArea{1..3}_a.Val
  swc implementation EPB_SysSrvAdpVDA_Implementation: behavior=EPB_SysSrvAdpVDA_InternalBehavior
    code-descriptors:
      code Default: artifact-descriptors=autosar-engineering-object={short-label=Default, category=SWSRC}
package /UAES/ASW/Units
  4 x unit, all with factor-si-to-unit=1, offset-si-to-unit=0:
    A: display-name=A
    DegC: display-name=℃
    kN: display-name=kN
    NoUnit
